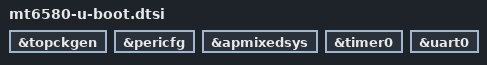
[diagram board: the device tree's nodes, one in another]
// SPDX-License-Identifier: GPL-2.0
/*
 * Copyright (c) 2023 Predefine
 */

&topckgen {
    bootph-all;
};

&pericfg {
    bootph-all;
};

&apmixedsys {
    bootph-all;
};

&timer0 {
    bootph-all;
};

&uart0 {
    bootph-all;
};
